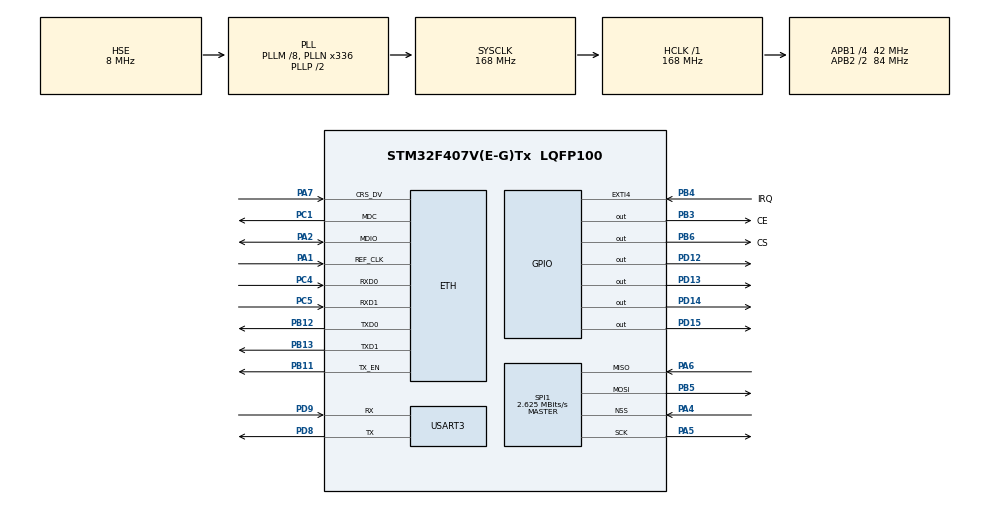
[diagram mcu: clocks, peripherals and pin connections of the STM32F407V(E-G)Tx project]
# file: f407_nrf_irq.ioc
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Mcu.Family=STM32F4
PA6.Mode=Full_Duplex_Master
PH0-OSC_IN.Signal=RCC_OSC_IN
RCC.CortexFreq_Value=168000000
SPI1.VirtualType=VM_MASTER
PB6.GPIO_Label=CS
PC5.Mode=RMII
PB11.Signal=ETH_TX_EN
PB13.Signal=ETH_TXD1
PD9.Mode=Asynchronous
RCC.SYSCLKSource=RCC_SYSCLKSOURCE_PLLCLK
ProjectManager.StackSize=0x400
PD13.Signal=GPIO_Output
PA4.Mode=NSS_Signal_Hard_Input
SPI1.Direction=SPI_DIRECTION_2LINES
RCC.HCLKFreq_Value=168000000
RCC.APB2TimFreq_Value=168000000
PB6.Signal=GPIO_Output
SPI1.CalculateBaudRate=2.625 MBits/s
PD8.Signal=USART3_TX
RCC.AHBFreq_Value=168000000
PH0-OSC_IN.Mode=HSE-External-Oscillator
RCC.HSE_VALUE=8000000
PB5.Mode=Full_Duplex_Master
SPI1.VirtualNSS=VM_NSSHARD
PH1-OSC_OUT.Mode=HSE-External-Oscillator
Mcu.Package=LQFP100
PA6.Signal=SPI1_MISO
PB12.Mode=RMII
PD12.Signal=GPIO_Output
RCC.APB2CLKDivider=RCC_HCLK_DIV2
RCC.APB1TimFreq_Value=84000000
PC5.Signal=ETH_RXD1
PB13.Mode=RMII
SPI1.BaudRatePrescaler=SPI_BAUDRATEPRESCALER_32
PD15.Signal=GPIO_Output
VP_TIM3_VS_ClockSourceINT.Mode=Internal
PC4.Mode=RMII
PB4.Signal=GPXTI4
PA5.Mode=Full_Duplex_Master
PB3.GPIO_Label=CE
RCC.PLLSourceVirtual=RCC_PLLSOURCE_HSE
NVIC.EXTI4_IRQn=true\:0\:0\:false\:false\:true\:true\:true
PA7.Mode=RMII
PC4.Signal=ETH_RXD0
PD9.Signal=USART3_RX
LWIP.LWIP_DHCP=0
RCC.APB1CLKDivider=RCC_HCLK_DIV4
VP_LWIP_VS_Enabled.Mode=Enabled
LWIP.LWIP_DNS=1
PB11.Mode=RMII
ProjectManager.TargetToolchain=TrueSTUDIO
RCC.LSE_VALUE=32768
PD8.Mode=Asynchronous
PA1.Signal=ETH_REF_CLK
PA5.Signal=SPI1_SCK
board=STM32F407G-DISC1
RCC.VCOOutputFreq_Value=336000000
NVIC.TIM3_IRQn=true\:0\:0\:false\:false\:true\:true\:true
RCC.APB2Freq_Value=84000000
PA1.Mode=RMII
PB4.GPIO_Label=IRQ
SPI1.Mode=SPI_MODE_MASTER
PH1-OSC_OUT.Signal=RCC_OSC_OUT
Mcu.Name=STM32F407V(E-G)Tx
PA2.Signal=ETH_MDIO
PD14.Signal=GPIO_Output
RCC.48MHZClocksFreq_Value=48000000
PB3.Signal=GPIO_Output
PA4.Signal=SPI1_NSS
RCC.SYSCLKFreq_VALUE=168000000
PB5.Signal=SPI1_MOSI
ETH.MediaInterface=ETH_MEDIA_INTERFACE_RMII
USART3.VirtualMode=VM_ASYNC
ProjectManager.HeapSize=0x200
LWIP.Version=v2.1.2_Cube
RCC.HSI_VALUE=16000000
RCC.PLLQ=7
NVIC.PriorityGroup=NVIC_PRIORITYGROUP_0
RCC.PLLM=8
RCC.PLLN=336
PA2.Mode=RMII
RCC.APB1Freq_Value=42000000
PC1.Signal=ETH_MDC
PB12.Signal=ETH_TXD0
PC1.Mode=RMII
PA7.Signal=ETH_CRS_DV

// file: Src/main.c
/* USER CODE BEGIN Header */
/**
  ******************************************************************************
  * @file           : main.c
  * @brief          : Main program body
  ******************************************************************************
  * @attention
  *
  * <h2><center>&copy; Copyright (c) 2020 STMicroelectronics.
  * All rights reserved.</center></h2>
  *
  * This software component is licensed by ST under Ultimate Liberty license
  * SLA0044, the "License"; You may not use this file except in compliance with
  * the License. You may obtain a copy of the License at:
  *                             www.st.com/SLA0044
  *
  ******************************************************************************
  */
/* USER CODE END Header */

#include "main.h"
#include "lwip.h"

/* USER CODE BEGIN Includes */
#include "stdio.h"
#include "stdint.h"
#include "string.h"
#include "nrf24l01.h"
#include <memory.h>
/* USER CODE END Includes */

/* USER CODE BEGIN PM */

static void error() {
    while (true) {
        HAL_GPIO_TogglePin(GPIOD, GPIO_PIN_14);
        HAL_Delay(100);
    }
}

static const uint8_t rx_address[5] = {1, 2, 3, 4, 5};
static const uint8_t tx_address[5] = {1, 2, 3, 4, 6};
nrf24l01 nrf;
uint32_t rx_data;
extern uint8_t buffer[1000];
uint8_t ffer[1000];
uint8_t buffer_send[4];
/* USER CODE END PM */

SPI_HandleTypeDef hspi1;

TIM_HandleTypeDef htim3;

UART_HandleTypeDef huart3;

void SystemClock_Config(void);
static void MX_GPIO_Init(void);
static void MX_SPI1_Init(void);
static void MX_TIM3_Init(void);
static void MX_USART3_UART_Init(void);

int main(void)
{
  /* USER CODE BEGIN 1 */
uint8_t buf[1000];
  /* USER CODE END 1 */

  /* MCU Configuration--------------------------------------------------------*/

  /* Reset of all peripherals, Initializes the Flash interface and the Systick. */
  HAL_Init();

  /* Configure the system clock */
  SystemClock_Config();

  /* Initialize all configured peripherals */
  MX_GPIO_Init();
  MX_SPI1_Init();
  MX_TIM3_Init();
//  MX_LWIP_Init();
  MX_USART3_UART_Init();
  /* USER CODE BEGIN 2 */
  HAL_GPIO_WritePin(GPIOC,GPIO_PIN_15,GPIO_PIN_SET);

  {
      nrf24l01_config config;
      config.data_rate        = NRF_DATA_RATE_1MBPS;
      config.tx_power         = NRF_TX_PWR_0dBm;
      config.crc_width        = NRF_CRC_WIDTH_1B;
      config.addr_width       = NRF_ADDR_WIDTH_5;
      config.payload_length   = 4;    // maximum is 32 bytes
      config.retransmit_count = 2;   // maximum is 15 times
      config.retransmit_delay = 0x0F; // 4000us, LSB:250us
      config.rf_channel       = 11;
      config.rx_address       = tx_address;
      config.tx_address       = rx_address;
      config.rx_buffer        = (uint8_t*)&rx_data;

      config.spi         = &hspi1;
      config.spi_timeout = 10; // milliseconds
      config.ce_port     = CE_GPIO_Port;
      config.ce_pin      = CE_Pin;
      config.csn_pin     = CS_Pin;
      config.csn_port    = CS_GPIO_Port;
      config.irq_port    = IRQ_GPIO_Port;
      config.irq_pin     = IRQ_Pin;

      nrf_init(&nrf, &config);
  }
  // nrf_send_packet_noack(&nrf, (uint8_t*)&tx_data);
  memset(ffer, 0, sizeof(ffer));
  sprintf(ffer,"hello world Mohamed from discovery board stm32f4 !\n\r");
  uint16_t i=0;
  i=sizeof(ffer);
 uint16_t u=0;
 while (i){
	  int t=4,g=0;
	  while (t){
		  t--;
		  if(ffer[u]!= 0){
			  buffer_send[g]=ffer[u];
		  g++;
		  u++;
		  }
		  else{
			  i=0;
		        break;

		  }
	  }
	  nrf_send_packet_noack(&nrf, buffer_send);
 }
  /* USER CODE END 2 */

  /* Infinite loop */
  /* USER CODE BEGIN WHILE */
  while (1)
  {
	      // nrf_receive_packet(&nrf);

        //    HAL_UART_Transmit(&huart3,rx_data,sizeof(rx_data),1000);
	        HAL_GPIO_TogglePin(GPIOD, GPIO_PIN_13);
	        HAL_Delay(500);
	/*  HAL_GPIO_WritePin(GPIOD,GPIO_PIN_12,GPIO_PIN_SET);
	  HAL_GPIO_WritePin(GPIOD,GPIO_PIN_13,GPIO_PIN_RESET);
	  HAL_GPIO_WritePin(GPIOD,GPIO_PIN_14,GPIO_PIN_RESET);
	  HAL_GPIO_WritePin(GPIOD,GPIO_PIN_15,GPIO_PIN_RESET);
	  HAL_Delay(250);
	  HAL_GPIO_WritePin(GPIOD,GPIO_PIN_12,GPIO_PIN_RESET);
	  HAL_GPIO_WritePin(GPIOD,GPIO_PIN_13,GPIO_PIN_SET);
	  HAL_GPIO_WritePin(GPIOD,GPIO_PIN_14,GPIO_PIN_RESET);
	  HAL_GPIO_WritePin(GPIOD,GPIO_PIN_15,GPIO_PIN_RESET);
	  HAL_Delay(250);
	  HAL_GPIO_WritePin(GPIOD,GPIO_PIN_12,GPIO_PIN_RESET);
	  HAL_GPIO_WritePin(GPIOD,GPIO_PIN_13,GPIO_PIN_RESET);
	  HAL_GPIO_WritePin(GPIOD,GPIO_PIN_14,GPIO_PIN_SET);
	  HAL_GPIO_WritePin(GPIOD,GPIO_PIN_15,GPIO_PIN_RESET);
	  HAL_Delay(250);
	  HAL_GPIO_WritePin(GPIOD,GPIO_PIN_12,GPIO_PIN_RESET);
	  HAL_GPIO_WritePin(GPIOD,GPIO_PIN_13,GPIO_PIN_RESET);
	  HAL_GPIO_WritePin(GPIOD,GPIO_PIN_14,GPIO_PIN_RESET);
	  HAL_GPIO_WritePin(GPIOD,GPIO_PIN_15,GPIO_PIN_SET);
	  HAL_Delay(250);
	  HAL_GPIO_WritePin(GPIOD,GPIO_PIN_12,GPIO_PIN_RESET);
	  HAL_GPIO_WritePin(GPIOD,GPIO_PIN_13,GPIO_PIN_RESET);
	  HAL_GPIO_WritePin(GPIOD,GPIO_PIN_14,GPIO_PIN_RESET);
	  HAL_GPIO_WritePin(GPIOD,GPIO_PIN_15,GPIO_PIN_RESET);*/
    /* USER CODE END WHILE */

  }
}

void SystemClock_Config(void)
{
  RCC_OscInitTypeDef RCC_OscInitStruct = {0};
  RCC_ClkInitTypeDef RCC_ClkInitStruct = {0};

  /** Configure the main internal regulator output voltage
  */
  __HAL_RCC_PWR_CLK_ENABLE();
  __HAL_PWR_VOLTAGESCALING_CONFIG(PWR_REGULATOR_VOLTAGE_SCALE1);
  /** Initializes the CPU, AHB and APB busses clocks
  */
  RCC_OscInitStruct.OscillatorType = RCC_OSCILLATORTYPE_HSE;
  RCC_OscInitStruct.HSEState = RCC_HSE_ON;
  RCC_OscInitStruct.PLL.PLLState = RCC_PLL_ON;
  RCC_OscInitStruct.PLL.PLLSource = RCC_PLLSOURCE_HSE;
  RCC_OscInitStruct.PLL.PLLM = 8;
  RCC_OscInitStruct.PLL.PLLN = 336;
  RCC_OscInitStruct.PLL.PLLP = RCC_PLLP_DIV2;
  RCC_OscInitStruct.PLL.PLLQ = 7;
  if (HAL_RCC_OscConfig(&RCC_OscInitStruct) != HAL_OK)
  {
    Error_Handler();
  }
  /** Initializes the CPU, AHB and APB busses clocks
  */
  RCC_ClkInitStruct.ClockType = RCC_CLOCKTYPE_HCLK|RCC_CLOCKTYPE_SYSCLK
                              |RCC_CLOCKTYPE_PCLK1|RCC_CLOCKTYPE_PCLK2;
  RCC_ClkInitStruct.SYSCLKSource = RCC_SYSCLKSOURCE_PLLCLK;
  RCC_ClkInitStruct.AHBCLKDivider = RCC_SYSCLK_DIV1;
  RCC_ClkInitStruct.APB1CLKDivider = RCC_HCLK_DIV4;
  RCC_ClkInitStruct.APB2CLKDivider = RCC_HCLK_DIV2;

  if (HAL_RCC_ClockConfig(&RCC_ClkInitStruct, FLASH_LATENCY_5) != HAL_OK)
  {
    Error_Handler();
  }
}

static void MX_SPI1_Init(void)
{

  /* SPI1 parameter configuration*/
  hspi1.Instance = SPI1;
  hspi1.Init.Mode = SPI_MODE_MASTER;
  hspi1.Init.Direction = SPI_DIRECTION_2LINES;
  hspi1.Init.DataSize = SPI_DATASIZE_8BIT;
  hspi1.Init.CLKPolarity = SPI_POLARITY_LOW;
  hspi1.Init.CLKPhase = SPI_PHASE_1EDGE;
  hspi1.Init.NSS = SPI_NSS_HARD_OUTPUT;
  hspi1.Init.BaudRatePrescaler = SPI_BAUDRATEPRESCALER_32;
  hspi1.Init.FirstBit = SPI_FIRSTBIT_MSB;
  hspi1.Init.TIMode = SPI_TIMODE_DISABLE;
  hspi1.Init.CRCCalculation = SPI_CRCCALCULATION_DISABLE;
  hspi1.Init.CRCPolynomial = 10;
  if (HAL_SPI_Init(&hspi1) != HAL_OK)
  {
    Error_Handler();
  }

}

static void MX_TIM3_Init(void)
{

  TIM_ClockConfigTypeDef sClockSourceConfig = {0};
  TIM_MasterConfigTypeDef sMasterConfig = {0};

  htim3.Instance = TIM3;
  htim3.Init.Prescaler = 0;
  htim3.Init.CounterMode = TIM_COUNTERMODE_UP;
  htim3.Init.Period = 0;
  htim3.Init.ClockDivision = TIM_CLOCKDIVISION_DIV1;
  htim3.Init.AutoReloadPreload = TIM_AUTORELOAD_PRELOAD_DISABLE;
  if (HAL_TIM_Base_Init(&htim3) != HAL_OK)
  {
    Error_Handler();
  }
  sClockSourceConfig.ClockSource = TIM_CLOCKSOURCE_INTERNAL;
  if (HAL_TIM_ConfigClockSource(&htim3, &sClockSourceConfig) != HAL_OK)
  {
    Error_Handler();
  }
  sMasterConfig.MasterOutputTrigger = TIM_TRGO_RESET;
  sMasterConfig.MasterSlaveMode = TIM_MASTERSLAVEMODE_DISABLE;
  if (HAL_TIMEx_MasterConfigSynchronization(&htim3, &sMasterConfig) != HAL_OK)
  {
    Error_Handler();
  }

}

static void MX_USART3_UART_Init(void)
{

  huart3.Instance = USART3;
  huart3.Init.BaudRate = 115200;
  huart3.Init.WordLength = UART_WORDLENGTH_8B;
  huart3.Init.StopBits = UART_STOPBITS_1;
  huart3.Init.Parity = UART_PARITY_NONE;
  huart3.Init.Mode = UART_MODE_TX_RX;
  huart3.Init.HwFlowCtl = UART_HWCONTROL_NONE;
  huart3.Init.OverSampling = UART_OVERSAMPLING_16;
  if (HAL_UART_Init(&huart3) != HAL_OK)
  {
    Error_Handler();
  }

}

static void MX_GPIO_Init(void)
{
  GPIO_InitTypeDef GPIO_InitStruct = {0};

  /* GPIO Ports Clock Enable */
  __HAL_RCC_GPIOH_CLK_ENABLE();
  __HAL_RCC_GPIOC_CLK_ENABLE();
  __HAL_RCC_GPIOA_CLK_ENABLE();
  __HAL_RCC_GPIOB_CLK_ENABLE();
  __HAL_RCC_GPIOD_CLK_ENABLE();

  /*Configure GPIO pin Output Level */
  HAL_GPIO_WritePin(GPIOD, GPIO_PIN_12|GPIO_PIN_13|GPIO_PIN_14|GPIO_PIN_15, GPIO_PIN_RESET);
  HAL_GPIO_WritePin(GPIOC, GPIO_PIN_15, GPIO_PIN_RESET);

  /*Configure GPIO pin Output Level */
  HAL_GPIO_WritePin(GPIOB, CE_Pin|CS_Pin, GPIO_PIN_RESET);

  /*Configure GPIO pins : PD12 PD13 PD14 PD15 */
  GPIO_InitStruct.Pin = GPIO_PIN_12|GPIO_PIN_13|GPIO_PIN_14|GPIO_PIN_15;
  GPIO_InitStruct.Mode = GPIO_MODE_OUTPUT_PP;
  GPIO_InitStruct.Pull = GPIO_NOPULL;
  GPIO_InitStruct.Speed = GPIO_SPEED_FREQ_HIGH;
  HAL_GPIO_Init(GPIOD, &GPIO_InitStruct);
  GPIO_InitStruct.Pin = GPIO_PIN_15;
  GPIO_InitStruct.Mode = GPIO_MODE_OUTPUT_PP;
  GPIO_InitStruct.Pull = GPIO_NOPULL;
  GPIO_InitStruct.Speed = GPIO_SPEED_FREQ_HIGH;
  HAL_GPIO_Init(GPIOC, &GPIO_InitStruct);

  /*Configure GPIO pins : CE_Pin CS_Pin */
  GPIO_InitStruct.Pin = CE_Pin|CS_Pin;
  GPIO_InitStruct.Mode = GPIO_MODE_OUTPUT_PP;
  GPIO_InitStruct.Pull = GPIO_NOPULL;
  GPIO_InitStruct.Speed = GPIO_SPEED_FREQ_HIGH;
  HAL_GPIO_Init(GPIOB, &GPIO_InitStruct);

  /*Configure GPIO pin : IRQ_Pin */
  GPIO_InitStruct.Pin = IRQ_Pin;
  GPIO_InitStruct.Mode = GPIO_MODE_IT_FALLING;
  GPIO_InitStruct.Pull = GPIO_NOPULL;
  HAL_GPIO_Init(IRQ_GPIO_Port, &GPIO_InitStruct);

  /* EXTI interrupt init*/
  HAL_NVIC_SetPriority(EXTI4_IRQn, 0, 0);
  HAL_NVIC_EnableIRQ(EXTI4_IRQn);

}

/* USER CODE BEGIN 4 */
void HAL_GPIO_EXTI_Callback(uint16_t GPIO_Pin)
{
	if(GPIO_Pin==IRQ_Pin){
	 //   sprintf(buffer,"IRQ triggired \n\r");
	  //  HAL_UART_Transmit(&huart3,buffer,strlen(buffer),1000);
		HAL_GPIO_TogglePin(GPIOD,GPIO_PIN_15);
	    nrf_irq_handler(&nrf);
	}
}
/* USER CODE END 4 */

void Error_Handler(void)
{
}

/************************ (C) COPYRIGHT STMicroelectronics *****END OF FILE****/
